# F28x7x_pie_ctrl_regs register map
Vendor: Texas Instruments
Peripheral module from a debugger description file (folder C2000).
Address unit: 16 bits
Registers are 16-bit, read-write, no defined reset value unless marked. A register's access mark holds for its fields unless they carry their own. Offsets are as the file gives them; lines under a group give offsets from that group; [hi:lo] are bit positions; {n}, {i} and the like mark numbered series; 'fields as' and 'values as' point back to an identical list; <NAME> marks a mode.

## PIE_CTRL_REGS — PIE CTRL Registers
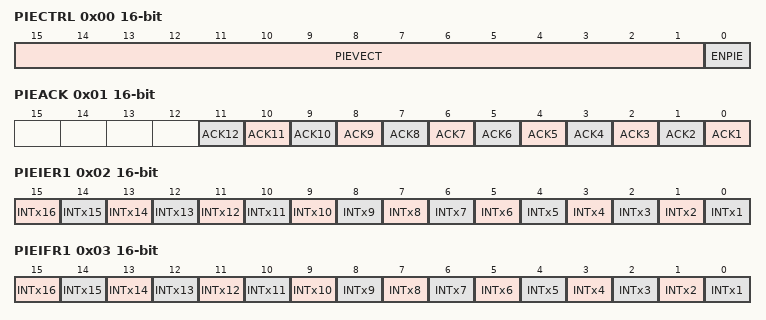
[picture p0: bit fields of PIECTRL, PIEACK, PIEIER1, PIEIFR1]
0x00 PIECTRL access per field — ePIE Control Register
  [15:1] PIEVECT ro — PIE Vector Address
  [0] ENPIE rw — PIE Enable
0x01 PIEACK access not given — Interrupt Acknowledge Register
  [n-1] ACK{n} (n=1..12) — Acknowledge PIE Interrupt Group {n} (access R/W=1)
0x02 PIEIER1 — Interrupt Group 1 Enable Register
  [15] INTx16 — Enable for Interrupt 1.16
  [14] INTx15 — Enable for Interrupt 1.15
  [13] INTx14 — Enable for Interrupt 1.14
  [12] INTx13 — Enable for Interrupt 1.13
  [11] INTx12 — Enable for Interrupt 1.12
  [10] INTx11 — Enable for Interrupt 1.11
  [9] INTx10 — Enable for Interrupt 1.10
  [8] INTx9 — Enable for Interrupt 1.9
  [7] INTx8 — Enable for Interrupt 1.8
  [6] INTx7 — Enable for Interrupt 1.7
  [5] INTx6 — Enable for Interrupt 1.6
  [4] INTx5 — Enable for Interrupt 1.5
  [3] INTx4 — Enable for Interrupt 1.4
  [2] INTx3 — Enable for Interrupt 1.3
  [1] INTx2 — Enable for Interrupt 1.2
  [0] INTx1 — Enable for Interrupt 1.1
0x03 PIEIFR1 — Interrupt Group 1 Flag Register
  [15] INTx16 — Flag for Interrupt 1.16
  [14] INTx15 — Flag for Interrupt 1.15
  [13] INTx14 — Flag for Interrupt 1.14
  [12] INTx13 — Flag for Interrupt 1.13
  [11] INTx12 — Flag for Interrupt 1.12
  [10] INTx11 — Flag for Interrupt 1.11
  [9] INTx10 — Flag for Interrupt 1.10
  [8] INTx9 — Flag for Interrupt 1.9
  [7] INTx8 — Flag for Interrupt 1.8
  [6] INTx7 — Flag for Interrupt 1.7
  [5] INTx6 — Flag for Interrupt 1.6
  [4] INTx5 — Flag for Interrupt 1.5
  [3] INTx4 — Flag for Interrupt 1.4
  [2] INTx3 — Flag for Interrupt 1.3
  [1] INTx2 — Flag for Interrupt 1.2
  [0] INTx1 — Flag for Interrupt 1.1
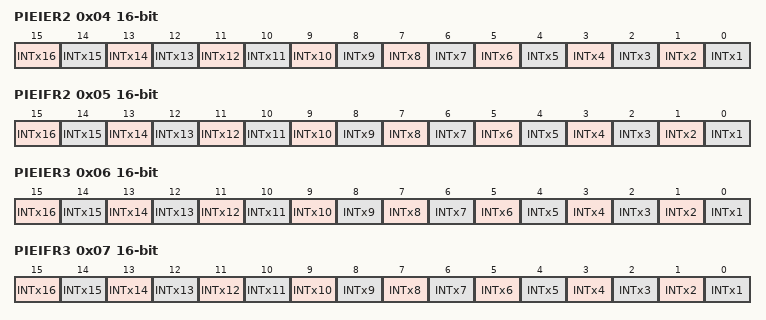
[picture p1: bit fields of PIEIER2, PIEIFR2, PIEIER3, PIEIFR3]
0x04 PIEIER2 — Interrupt Group 2 Enable Register
  [15] INTx16 — Enable for Interrupt 2.16
  [14] INTx15 — Enable for Interrupt 2.15
  [13] INTx14 — Enable for Interrupt 2.14
  [12] INTx13 — Enable for Interrupt 2.13
  [11] INTx12 — Enable for Interrupt 2.12
  [10] INTx11 — Enable for Interrupt 2.11
  [9] INTx10 — Enable for Interrupt 2.10
  [8] INTx9 — Enable for Interrupt 2.9
  [7] INTx8 — Enable for Interrupt 2.8
  [6] INTx7 — Enable for Interrupt 2.7
  [5] INTx6 — Enable for Interrupt 2.6
  [4] INTx5 — Enable for Interrupt 2.5
  [3] INTx4 — Enable for Interrupt 2.4
  [2] INTx3 — Enable for Interrupt 2.3
  [1] INTx2 — Enable for Interrupt 2.2
  [0] INTx1 — Enable for Interrupt 2.1
0x05 PIEIFR2 — Interrupt Group 2 Flag Register
  [15] INTx16 — Flag for Interrupt 2.16
  [14] INTx15 — Flag for Interrupt 2.15
  [13] INTx14 — Flag for Interrupt 2.14
  [12] INTx13 — Flag for Interrupt 2.13
  [11] INTx12 — Flag for Interrupt 2.12
  [10] INTx11 — Flag for Interrupt 2.11
  [9] INTx10 — Flag for Interrupt 2.10
  [8] INTx9 — Flag for Interrupt 2.9
  [7] INTx8 — Flag for Interrupt 2.8
  [6] INTx7 — Flag for Interrupt 2.7
  [5] INTx6 — Flag for Interrupt 2.6
  [4] INTx5 — Flag for Interrupt 2.5
  [3] INTx4 — Flag for Interrupt 2.4
  [2] INTx3 — Flag for Interrupt 2.3
  [1] INTx2 — Flag for Interrupt 2.2
  [0] INTx1 — Flag for Interrupt 2.1
0x06 PIEIER3 — Interrupt Group 3 Enable Register
  [15] INTx16 — Enable for Interrupt 3.16
  [14] INTx15 — Enable for Interrupt 3.15
  [13] INTx14 — Enable for Interrupt 3.14
  [12] INTx13 — Enable for Interrupt 3.13
  [11] INTx12 — Enable for Interrupt 3.12
  [10] INTx11 — Enable for Interrupt 3.11
  [9] INTx10 — Enable for Interrupt 3.10
  [8] INTx9 — Enable for Interrupt 3.9
  [7] INTx8 — Enable for Interrupt 3.8
  [6] INTx7 — Enable for Interrupt 3.7
  [5] INTx6 — Enable for Interrupt 3.6
  [4] INTx5 — Enable for Interrupt 3.5
  [3] INTx4 — Enable for Interrupt 3.4
  [2] INTx3 — Enable for Interrupt 3.3
  [1] INTx2 — Enable for Interrupt 3.2
  [0] INTx1 — Enable for Interrupt 3.1
0x07 PIEIFR3 — Interrupt Group 3 Flag Register
  [15] INTx16 — Flag for Interrupt 3.16
  [14] INTx15 — Flag for Interrupt 3.15
  [13] INTx14 — Flag for Interrupt 3.14
  [12] INTx13 — Flag for Interrupt 3.13
  [11] INTx12 — Flag for Interrupt 3.12
  [10] INTx11 — Flag for Interrupt 3.11
  [9] INTx10 — Flag for Interrupt 3.10
  [8] INTx9 — Flag for Interrupt 3.9
  [7] INTx8 — Flag for Interrupt 3.8
  [6] INTx7 — Flag for Interrupt 3.7
  [5] INTx6 — Flag for Interrupt 3.6
  [4] INTx5 — Flag for Interrupt 3.5
  [3] INTx4 — Flag for Interrupt 3.4
  [2] INTx3 — Flag for Interrupt 3.3
  [1] INTx2 — Flag for Interrupt 3.2
  [0] INTx1 — Flag for Interrupt 3.1
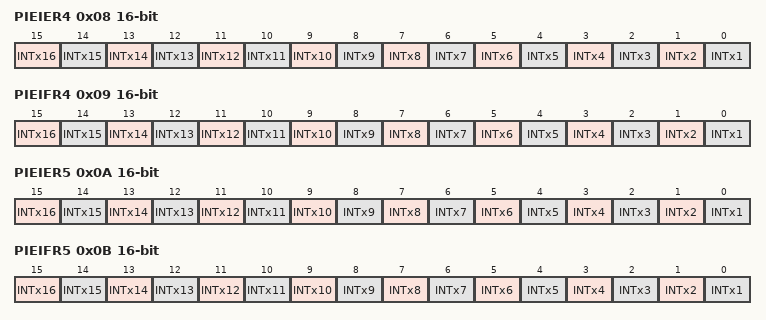
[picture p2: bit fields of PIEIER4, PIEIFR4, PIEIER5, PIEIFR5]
0x08 PIEIER4 — Interrupt Group 4 Enable Register
  [15] INTx16 — Enable for Interrupt 4.16
  [14] INTx15 — Enable for Interrupt 4.15
  [13] INTx14 — Enable for Interrupt 4.14
  [12] INTx13 — Enable for Interrupt 4.13
  [11] INTx12 — Enable for Interrupt 4.12
  [10] INTx11 — Enable for Interrupt 4.11
  [9] INTx10 — Enable for Interrupt 4.10
  [8] INTx9 — Enable for Interrupt 4.9
  [7] INTx8 — Enable for Interrupt 4.8
  [6] INTx7 — Enable for Interrupt 4.7
  [5] INTx6 — Enable for Interrupt 4.6
  [4] INTx5 — Enable for Interrupt 4.5
  [3] INTx4 — Enable for Interrupt 4.4
  [2] INTx3 — Enable for Interrupt 4.3
  [1] INTx2 — Enable for Interrupt 4.2
  [0] INTx1 — Enable for Interrupt 4.1
0x09 PIEIFR4 — Interrupt Group 4 Flag Register
  [15] INTx16 — Flag for Interrupt 4.16
  [14] INTx15 — Flag for Interrupt 4.15
  [13] INTx14 — Flag for Interrupt 4.14
  [12] INTx13 — Flag for Interrupt 4.13
  [11] INTx12 — Flag for Interrupt 4.12
  [10] INTx11 — Flag for Interrupt 4.11
  [9] INTx10 — Flag for Interrupt 4.10
  [8] INTx9 — Flag for Interrupt 4.9
  [7] INTx8 — Flag for Interrupt 4.8
  [6] INTx7 — Flag for Interrupt 4.7
  [5] INTx6 — Flag for Interrupt 4.6
  [4] INTx5 — Flag for Interrupt 4.5
  [3] INTx4 — Flag for Interrupt 4.4
  [2] INTx3 — Flag for Interrupt 4.3
  [1] INTx2 — Flag for Interrupt 4.2
  [0] INTx1 — Flag for Interrupt 4.1
0x0A PIEIER5 — Interrupt Group 5 Enable Register
  [15] INTx16 — Enable for Interrupt 5.16
  [14] INTx15 — Enable for Interrupt 5.15
  [13] INTx14 — Enable for Interrupt 5.14
  [12] INTx13 — Enable for Interrupt 5.13
  [11] INTx12 — Enable for Interrupt 5.12
  [10] INTx11 — Enable for Interrupt 5.11
  [9] INTx10 — Enable for Interrupt 5.10
  [8] INTx9 — Enable for Interrupt 5.9
  [7] INTx8 — Enable for Interrupt 5.8
  [6] INTx7 — Enable for Interrupt 5.7
  [5] INTx6 — Enable for Interrupt 5.6
  [4] INTx5 — Enable for Interrupt 5.5
  [3] INTx4 — Enable for Interrupt 5.4
  [2] INTx3 — Enable for Interrupt 5.3
  [1] INTx2 — Enable for Interrupt 5.2
  [0] INTx1 — Enable for Interrupt 5.1
0x0B PIEIFR5 — Interrupt Group 5 Flag Register
  [15] INTx16 — Flag for Interrupt 5.16
  [14] INTx15 — Flag for Interrupt 5.15
  [13] INTx14 — Flag for Interrupt 5.14
  [12] INTx13 — Flag for Interrupt 5.13
  [11] INTx12 — Flag for Interrupt 5.12
  [10] INTx11 — Flag for Interrupt 5.11
  [9] INTx10 — Flag for Interrupt 5.10
  [8] INTx9 — Flag for Interrupt 5.9
  [7] INTx8 — Flag for Interrupt 5.8
  [6] INTx7 — Flag for Interrupt 5.7
  [5] INTx6 — Flag for Interrupt 5.6
  [4] INTx5 — Flag for Interrupt 5.5
  [3] INTx4 — Flag for Interrupt 5.4
  [2] INTx3 — Flag for Interrupt 5.3
  [1] INTx2 — Flag for Interrupt 5.2
  [0] INTx1 — Flag for Interrupt 5.1
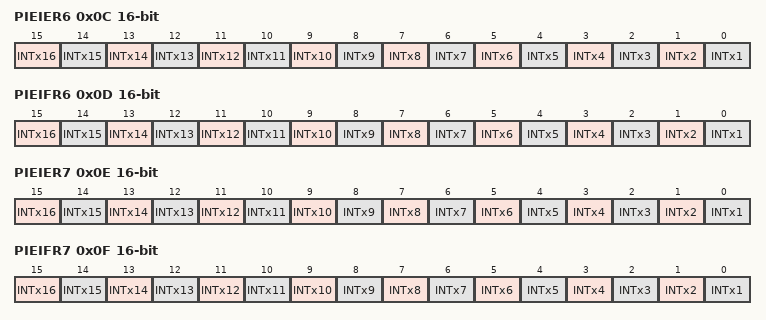
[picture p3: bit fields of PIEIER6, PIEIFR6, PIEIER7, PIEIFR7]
0x0C PIEIER6 — Interrupt Group 6 Enable Register
  [15] INTx16 — Enable for Interrupt 6.16
  [14] INTx15 — Enable for Interrupt 6.15
  [13] INTx14 — Enable for Interrupt 6.14
  [12] INTx13 — Enable for Interrupt 6.13
  [11] INTx12 — Enable for Interrupt 6.12
  [10] INTx11 — Enable for Interrupt 6.11
  [9] INTx10 — Enable for Interrupt 6.10
  [8] INTx9 — Enable for Interrupt 6.9
  [7] INTx8 — Enable for Interrupt 6.8
  [6] INTx7 — Enable for Interrupt 6.7
  [5] INTx6 — Enable for Interrupt 6.6
  [4] INTx5 — Enable for Interrupt 6.5
  [3] INTx4 — Enable for Interrupt 6.4
  [2] INTx3 — Enable for Interrupt 6.3
  [1] INTx2 — Enable for Interrupt 6.2
  [0] INTx1 — Enable for Interrupt 6.1
0x0D PIEIFR6 — Interrupt Group 6 Flag Register
  [15] INTx16 — Flag for Interrupt 6.16
  [14] INTx15 — Flag for Interrupt 6.15
  [13] INTx14 — Flag for Interrupt 6.14
  [12] INTx13 — Flag for Interrupt 6.13
  [11] INTx12 — Flag for Interrupt 6.12
  [10] INTx11 — Flag for Interrupt 6.11
  [9] INTx10 — Flag for Interrupt 6.10
  [8] INTx9 — Flag for Interrupt 6.9
  [7] INTx8 — Flag for Interrupt 6.8
  [6] INTx7 — Flag for Interrupt 6.7
  [5] INTx6 — Flag for Interrupt 6.6
  [4] INTx5 — Flag for Interrupt 6.5
  [3] INTx4 — Flag for Interrupt 6.4
  [2] INTx3 — Flag for Interrupt 6.3
  [1] INTx2 — Flag for Interrupt 6.2
  [0] INTx1 — Flag for Interrupt 6.1
0x0E PIEIER7 — Interrupt Group 7 Enable Register
  [15] INTx16 — Enable for Interrupt 7.16
  [14] INTx15 — Enable for Interrupt 7.15
  [13] INTx14 — Enable for Interrupt 7.14
  [12] INTx13 — Enable for Interrupt 7.13
  [11] INTx12 — Enable for Interrupt 7.12
  [10] INTx11 — Enable for Interrupt 7.11
  [9] INTx10 — Enable for Interrupt 7.10
  [8] INTx9 — Enable for Interrupt 7.9
  [7] INTx8 — Enable for Interrupt 7.8
  [6] INTx7 — Enable for Interrupt 7.7
  [5] INTx6 — Enable for Interrupt 7.6
  [4] INTx5 — Enable for Interrupt 7.5
  [3] INTx4 — Enable for Interrupt 7.4
  [2] INTx3 — Enable for Interrupt 7.3
  [1] INTx2 — Enable for Interrupt 7.2
  [0] INTx1 — Enable for Interrupt 7.1
0x0F PIEIFR7 — Interrupt Group 7 Flag Register
  [15] INTx16 — Flag for Interrupt 7.16
  [14] INTx15 — Flag for Interrupt 7.15
  [13] INTx14 — Flag for Interrupt 7.14
  [12] INTx13 — Flag for Interrupt 7.13
  [11] INTx12 — Flag for Interrupt 7.12
  [10] INTx11 — Flag for Interrupt 7.11
  [9] INTx10 — Flag for Interrupt 7.10
  [8] INTx9 — Flag for Interrupt 7.9
  [7] INTx8 — Flag for Interrupt 7.8
  [6] INTx7 — Flag for Interrupt 7.7
  [5] INTx6 — Flag for Interrupt 7.6
  [4] INTx5 — Flag for Interrupt 7.5
  [3] INTx4 — Flag for Interrupt 7.4
  [2] INTx3 — Flag for Interrupt 7.3
  [1] INTx2 — Flag for Interrupt 7.2
  [0] INTx1 — Flag for Interrupt 7.1
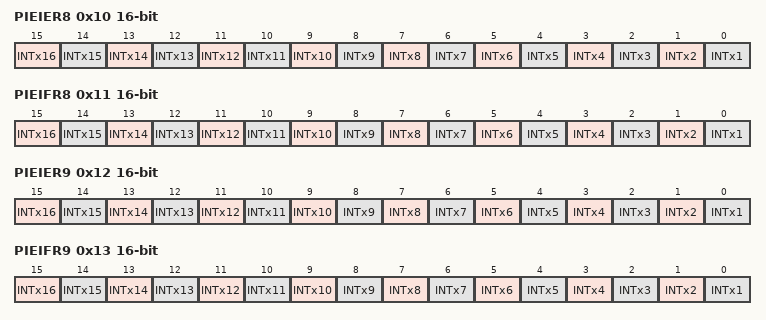
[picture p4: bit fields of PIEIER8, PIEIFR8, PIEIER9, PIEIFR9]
0x10 PIEIER8 — Interrupt Group 8 Enable Register
  [15] INTx16 — Enable for Interrupt 8.16
  [14] INTx15 — Enable for Interrupt 8.15
  [13] INTx14 — Enable for Interrupt 8.14
  [12] INTx13 — Enable for Interrupt 8.13
  [11] INTx12 — Enable for Interrupt 8.12
  [10] INTx11 — Enable for Interrupt 8.11
  [9] INTx10 — Enable for Interrupt 8.10
  [8] INTx9 — Enable for Interrupt 8.9
  [7] INTx8 — Enable for Interrupt 8.8
  [6] INTx7 — Enable for Interrupt 8.7
  [5] INTx6 — Enable for Interrupt 8.6
  [4] INTx5 — Enable for Interrupt 8.5
  [3] INTx4 — Enable for Interrupt 8.4
  [2] INTx3 — Enable for Interrupt 8.3
  [1] INTx2 — Enable for Interrupt 8.2
  [0] INTx1 — Enable for Interrupt 8.1
0x11 PIEIFR8 — Interrupt Group 8 Flag Register
  [15] INTx16 — Flag for Interrupt 8.16
  [14] INTx15 — Flag for Interrupt 8.15
  [13] INTx14 — Flag for Interrupt 8.14
  [12] INTx13 — Flag for Interrupt 8.13
  [11] INTx12 — Flag for Interrupt 8.12
  [10] INTx11 — Flag for Interrupt 8.11
  [9] INTx10 — Flag for Interrupt 8.10
  [8] INTx9 — Flag for Interrupt 8.9
  [7] INTx8 — Flag for Interrupt 8.8
  [6] INTx7 — Flag for Interrupt 8.7
  [5] INTx6 — Flag for Interrupt 8.6
  [4] INTx5 — Flag for Interrupt 8.5
  [3] INTx4 — Flag for Interrupt 8.4
  [2] INTx3 — Flag for Interrupt 8.3
  [1] INTx2 — Flag for Interrupt 8.2
  [0] INTx1 — Flag for Interrupt 8.1
0x12 PIEIER9 — Interrupt Group 9 Enable Register
  [15] INTx16 — Enable for Interrupt 9.16
  [14] INTx15 — Enable for Interrupt 9.15
  [13] INTx14 — Enable for Interrupt 9.14
  [12] INTx13 — Enable for Interrupt 9.13
  [11] INTx12 — Enable for Interrupt 9.12
  [10] INTx11 — Enable for Interrupt 9.11
  [9] INTx10 — Enable for Interrupt 9.10
  [8] INTx9 — Enable for Interrupt 9.9
  [7] INTx8 — Enable for Interrupt 9.8
  [6] INTx7 — Enable for Interrupt 9.7
  [5] INTx6 — Enable for Interrupt 9.6
  [4] INTx5 — Enable for Interrupt 9.5
  [3] INTx4 — Enable for Interrupt 9.4
  [2] INTx3 — Enable for Interrupt 9.3
  [1] INTx2 — Enable for Interrupt 9.2
  [0] INTx1 — Enable for Interrupt 9.1
0x13 PIEIFR9 — Interrupt Group 9 Flag Register
  [15] INTx16 — Flag for Interrupt 9.16
  [14] INTx15 — Flag for Interrupt 9.15
  [13] INTx14 — Flag for Interrupt 9.14
  [12] INTx13 — Flag for Interrupt 9.13
  [11] INTx12 — Flag for Interrupt 9.12
  [10] INTx11 — Flag for Interrupt 9.11
  [9] INTx10 — Flag for Interrupt 9.10
  [8] INTx9 — Flag for Interrupt 9.9
  [7] INTx8 — Flag for Interrupt 9.8
  [6] INTx7 — Flag for Interrupt 9.7
  [5] INTx6 — Flag for Interrupt 9.6
  [4] INTx5 — Flag for Interrupt 9.5
  [3] INTx4 — Flag for Interrupt 9.4
  [2] INTx3 — Flag for Interrupt 9.3
  [1] INTx2 — Flag for Interrupt 9.2
  [0] INTx1 — Flag for Interrupt 9.1
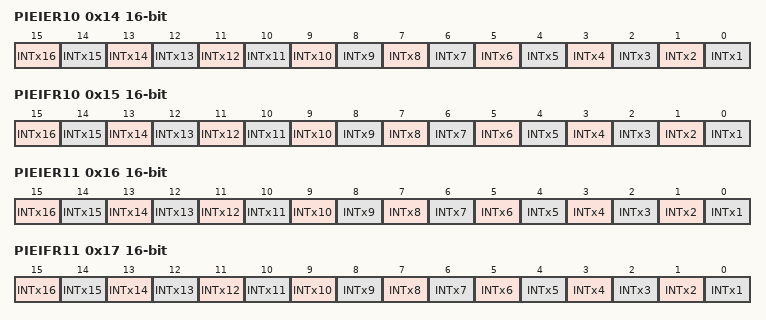
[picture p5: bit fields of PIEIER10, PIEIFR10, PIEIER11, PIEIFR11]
0x14 PIEIER10 — Interrupt Group 10 Enable Register
  [15] INTx16 — Enable for Interrupt 10.16
  [14] INTx15 — Enable for Interrupt 10.15
  [13] INTx14 — Enable for Interrupt 10.14
  [12] INTx13 — Enable for Interrupt 10.13
  [11] INTx12 — Enable for Interrupt 10.12
  [10] INTx11 — Enable for Interrupt 10.11
  [9] INTx10 — Enable for Interrupt 10.10
  [8] INTx9 — Enable for Interrupt 10.9
  [7] INTx8 — Enable for Interrupt 10.8
  [6] INTx7 — Enable for Interrupt 10.7
  [5] INTx6 — Enable for Interrupt 10.6
  [4] INTx5 — Enable for Interrupt 10.5
  [3] INTx4 — Enable for Interrupt 10.4
  [2] INTx3 — Enable for Interrupt 10.3
  [1] INTx2 — Enable for Interrupt 10.2
  [0] INTx1 — Enable for Interrupt 10.1
0x15 PIEIFR10 — Interrupt Group 10 Flag Register
  [15] INTx16 — Flag for Interrupt 10.16
  [14] INTx15 — Flag for Interrupt 10.15
  [13] INTx14 — Flag for Interrupt 10.14
  [12] INTx13 — Flag for Interrupt 10.13
  [11] INTx12 — Flag for Interrupt 10.12
  [10] INTx11 — Flag for Interrupt 10.11
  [9] INTx10 — Flag for Interrupt 10.10
  [8] INTx9 — Flag for Interrupt 10.9
  [7] INTx8 — Flag for Interrupt 10.8
  [6] INTx7 — Flag for Interrupt 10.7
  [5] INTx6 — Flag for Interrupt 10.6
  [4] INTx5 — Flag for Interrupt 10.5
  [3] INTx4 — Flag for Interrupt 10.4
  [2] INTx3 — Flag for Interrupt 10.3
  [1] INTx2 — Flag for Interrupt 10.2
  [0] INTx1 — Flag for Interrupt 10.1
0x16 PIEIER11 — Interrupt Group 11 Enable Register
  [15] INTx16 — Enable for Interrupt 11.16
  [14] INTx15 — Enable for Interrupt 11.15
  [13] INTx14 — Enable for Interrupt 11.14
  [12] INTx13 — Enable for Interrupt 11.13
  [11] INTx12 — Enable for Interrupt 11.12
  [10] INTx11 — Enable for Interrupt 11.11
  [9] INTx10 — Enable for Interrupt 11.10
  [8] INTx9 — Enable for Interrupt 11.9
  [7] INTx8 — Enable for Interrupt 11.8
  [6] INTx7 — Enable for Interrupt 11.7
  [5] INTx6 — Enable for Interrupt 11.6
  [4] INTx5 — Enable for Interrupt 11.5
  [3] INTx4 — Enable for Interrupt 11.4
  [2] INTx3 — Enable for Interrupt 11.3
  [1] INTx2 — Enable for Interrupt 11.2
  [0] INTx1 — Enable for Interrupt 11.1
0x17 PIEIFR11 — Interrupt Group 11 Flag Register
  [15] INTx16 — Flag for Interrupt 11.16
  [14] INTx15 — Flag for Interrupt 11.15
  [13] INTx14 — Flag for Interrupt 11.14
  [12] INTx13 — Flag for Interrupt 11.13
  [11] INTx12 — Flag for Interrupt 11.12
  [10] INTx11 — Flag for Interrupt 11.11
  [9] INTx10 — Flag for Interrupt 11.10
  [8] INTx9 — Flag for Interrupt 11.9
  [7] INTx8 — Flag for Interrupt 11.8
  [6] INTx7 — Flag for Interrupt 11.7
  [5] INTx6 — Flag for Interrupt 11.6
  [4] INTx5 — Flag for Interrupt 11.5
  [3] INTx4 — Flag for Interrupt 11.4
  [2] INTx3 — Flag for Interrupt 11.3
  [1] INTx2 — Flag for Interrupt 11.2
  [0] INTx1 — Flag for Interrupt 11.1
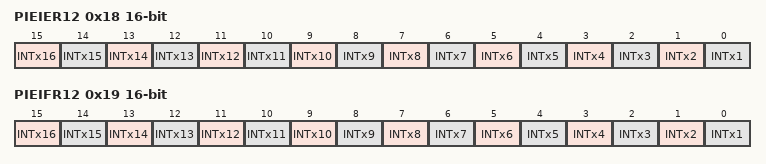
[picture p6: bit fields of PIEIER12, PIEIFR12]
0x18 PIEIER12 — Interrupt Group 12 Enable Register
  [15] INTx16 — Enable for Interrupt 12.16
  [14] INTx15 — Enable for Interrupt 12.15
  [13] INTx14 — Enable for Interrupt 12.14
  [12] INTx13 — Enable for Interrupt 12.13
  [11] INTx12 — Enable for Interrupt 12.12
  [10] INTx11 — Enable for Interrupt 12.11
  [9] INTx10 — Enable for Interrupt 12.10
  [8] INTx9 — Enable for Interrupt 12.9
  [7] INTx8 — Enable for Interrupt 12.8
  [6] INTx7 — Enable for Interrupt 12.7
  [5] INTx6 — Enable for Interrupt 12.6
  [4] INTx5 — Enable for Interrupt 12.5
  [3] INTx4 — Enable for Interrupt 12.4
  [2] INTx3 — Enable for Interrupt 12.3
  [1] INTx2 — Enable for Interrupt 12.2
  [0] INTx1 — Enable for Interrupt 12.1
0x19 PIEIFR12 — Interrupt Group 12 Flag Register
  [15] INTx16 — Flag for Interrupt 12.16
  [14] INTx15 — Flag for Interrupt 12.15
  [13] INTx14 — Flag for Interrupt 12.14
  [12] INTx13 — Flag for Interrupt 12.13
  [11] INTx12 — Flag for Interrupt 12.12
  [10] INTx11 — Flag for Interrupt 12.11
  [9] INTx10 — Flag for Interrupt 12.10
  [8] INTx9 — Flag for Interrupt 12.9
  [7] INTx8 — Flag for Interrupt 12.8
  [6] INTx7 — Flag for Interrupt 12.7
  [5] INTx6 — Flag for Interrupt 12.6
  [4] INTx5 — Flag for Interrupt 12.5
  [3] INTx4 — Flag for Interrupt 12.4
  [2] INTx3 — Flag for Interrupt 12.3
  [1] INTx2 — Flag for Interrupt 12.2
  [0] INTx1 — Flag for Interrupt 12.1
